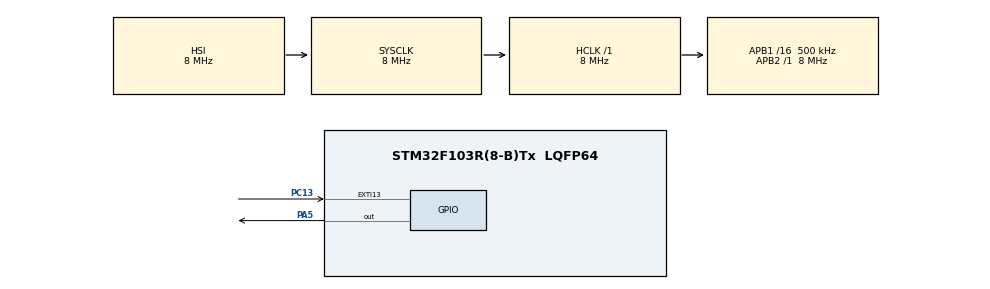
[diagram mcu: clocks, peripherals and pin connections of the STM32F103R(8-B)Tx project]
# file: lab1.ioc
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Mcu.Family=STM32F1
Mcu.Name=STM32F103R(8-B)Tx
Mcu.Package=LQFP64
NVIC.PriorityGroup=NVIC_PRIORITYGROUP_4
PA13.GPIO_Label=TMS
PA13.Mode=Serial_Wire
PA13.Signal=SYS_JTMS-SWDIO
PA14.GPIO_Label=TCK
PA14.Mode=Serial_Wire
PA14.Signal=SYS_JTCK-SWCLK
PA2.GPIO_Label=USART_TX
PA2.GPIO_Mode=GPIO_MODE_AF_PP
PA2.GPIO_PuPd=GPIO_NOPULL
PA2.GPIO_Speed=GPIO_SPEED_FREQ_LOW
PA2.Signal=USART2_TX
PA3.GPIO_Label=USART_RX
PA3.GPIO_Mode=GPIO_MODE_AF_PP
PA3.GPIO_PuPd=GPIO_NOPULL
PA3.GPIO_Speed=GPIO_SPEED_FREQ_LOW
PA3.Signal=USART2_RX
PA5.Signal=GPIO_Output
PB3.GPIO_Label=SWO
PB3.Signal=SYS_JTDO-TRACESWO
PB6.Signal=S_TIM4_CH1
PC13-TAMPER-RTC.Signal=GPXTI13
PC14-OSC32_IN.Signal=RCC_OSC32_IN
PC15-OSC32_OUT.Signal=RCC_OSC32_OUT
PD0-OSC_IN.Signal=RCC_OSC_IN
PD1-OSC_OUT.Signal=RCC_OSC_OUT
ProjectManager.HeapSize=0x200
ProjectManager.StackSize=0x400
ProjectManager.TargetToolchain=STM32CubeIDE
RCC.AHBFreq_Value=8000000
RCC.APB1CLKDivider=RCC_HCLK_DIV16
RCC.APB1Freq_Value=500000
RCC.APB1TimFreq_Value=1000000
RCC.APB2Freq_Value=8000000
RCC.APB2TimFreq_Value=8000000
RCC.HCLKFreq_Value=8000000
RCC.PLLMUL=RCC_PLL_MUL16
RCC.SYSCLKFreq_VALUE=8000000
RCC.USBFreq_Value=64000000
SH.S_TIM4_CH1.0=TIM4_CH1
TIM4.Period=65535
TIM4.Prescaler=10
VP_TIM4_VS_ClockSourceINT.Mode=Internal
board=NUCLEO-F103RB

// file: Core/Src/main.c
/* USER CODE BEGIN Header */
/**
  ******************************************************************************
  * @file           : main.c
  * @brief          : Main program body
  ******************************************************************************
  * @attention
  *
  * <h2><center>&copy; Copyright (c) 2020 STMicroelectronics.
  * All rights reserved.</center></h2>
  *
  * This software component is licensed by ST under BSD 3-Clause license,
  * the "License"; You may not use this file except in compliance with the
  * License. You may obtain a copy of the License at:
  *                        opensource.org/licenses/BSD-3-Clause
  *
  ******************************************************************************
  */
/* USER CODE END Header */

#include "main.h"

TIM_HandleTypeDef htim4;

void SystemClock_Config(void);
static void MX_GPIO_Init(void);
static void MX_TIM4_Init(void);

int main(void)
{

  /* MCU Configuration--------------------------------------------------------*/

  /* Reset of all peripherals, Initializes the Flash interface and the Systick. */
  HAL_Init();

  /* Configure the system clock */
  SystemClock_Config();

  /* Initialize all configured peripherals */
  MX_GPIO_Init();
  MX_TIM4_Init();

  /* Infinite loop */
  while (1)
  {

    /* USER CODE BEGIN 3 */
	  if(__HAL_TIM_GET_COUNTER(&htim4) == 0x00)
	  {
		  HAL_GPIO_TogglePin(GPIOA,GPIO_PIN_5);
	  }
	  //HAL_Delay(1000);
  }
  /* USER CODE END 3 */
}

void SystemClock_Config(void)
{
  RCC_OscInitTypeDef RCC_OscInitStruct = {0};
  RCC_ClkInitTypeDef RCC_ClkInitStruct = {0};

  /** Initializes the CPU, AHB and APB busses clocks
  */
  RCC_OscInitStruct.OscillatorType = RCC_OSCILLATORTYPE_HSI;
  RCC_OscInitStruct.HSIState = RCC_HSI_ON;
  RCC_OscInitStruct.HSICalibrationValue = RCC_HSICALIBRATION_DEFAULT;
  RCC_OscInitStruct.PLL.PLLState = RCC_PLL_NONE;
  if (HAL_RCC_OscConfig(&RCC_OscInitStruct) != HAL_OK)
  {
    Error_Handler();
  }
  /** Initializes the CPU, AHB and APB busses clocks
  */
  RCC_ClkInitStruct.ClockType = RCC_CLOCKTYPE_HCLK|RCC_CLOCKTYPE_SYSCLK
                              |RCC_CLOCKTYPE_PCLK1|RCC_CLOCKTYPE_PCLK2;
  RCC_ClkInitStruct.SYSCLKSource = RCC_SYSCLKSOURCE_HSI;
  RCC_ClkInitStruct.AHBCLKDivider = RCC_SYSCLK_DIV1;
  RCC_ClkInitStruct.APB1CLKDivider = RCC_HCLK_DIV16;
  RCC_ClkInitStruct.APB2CLKDivider = RCC_HCLK_DIV1;

  if (HAL_RCC_ClockConfig(&RCC_ClkInitStruct, FLASH_LATENCY_0) != HAL_OK)
  {
    Error_Handler();
  }
}

static void MX_TIM4_Init(void)
{

  TIM_ClockConfigTypeDef sClockSourceConfig = {0};
  TIM_MasterConfigTypeDef sMasterConfig = {0};

  /* USER CODE BEGIN TIM4_Init 1 */
  __HAL_RCC_TIM4_CLK_ENABLE();

  /* USER CODE END TIM4_Init 1 */
  htim4.Instance = TIM4;
  htim4.Init.Prescaler = 10;
  htim4.Init.CounterMode = TIM_COUNTERMODE_UP;
  htim4.Init.Period = 65535;
  htim4.Init.ClockDivision = TIM_CLOCKDIVISION_DIV1;
  htim4.Init.AutoReloadPreload = TIM_AUTORELOAD_PRELOAD_DISABLE;
  if (HAL_TIM_Base_Init(&htim4) != HAL_OK)
  {
    Error_Handler();
  }
  sClockSourceConfig.ClockSource = TIM_CLOCKSOURCE_INTERNAL;
  if (HAL_TIM_ConfigClockSource(&htim4, &sClockSourceConfig) != HAL_OK)
  {
    Error_Handler();
  }
  sMasterConfig.MasterOutputTrigger = TIM_TRGO_RESET;
  sMasterConfig.MasterSlaveMode = TIM_MASTERSLAVEMODE_DISABLE;
  if (HAL_TIMEx_MasterConfigSynchronization(&htim4, &sMasterConfig) != HAL_OK)
  {
    Error_Handler();
  }
  /* USER CODE BEGIN TIM4_Init 2 */
  HAL_TIM_Base_MspInit(&htim4);
  HAL_TIM_Base_Init(&htim4);
  HAL_TIM_Base_Start(&htim4);

  /* USER CODE END TIM4_Init 2 */

}

static void MX_GPIO_Init(void)
{
  GPIO_InitTypeDef GPIO_InitStruct = {0};

  /* GPIO Ports Clock Enable */
  __HAL_RCC_GPIOC_CLK_ENABLE();
  __HAL_RCC_GPIOD_CLK_ENABLE();
  __HAL_RCC_GPIOA_CLK_ENABLE();
  __HAL_RCC_GPIOB_CLK_ENABLE();

  /*Configure GPIO pin Output Level */
  HAL_GPIO_WritePin(GPIOA, GPIO_PIN_5, GPIO_PIN_RESET);

  /*Configure GPIO pin : PC13 */
  GPIO_InitStruct.Pin = GPIO_PIN_13;
  GPIO_InitStruct.Mode = GPIO_MODE_IT_RISING;
  GPIO_InitStruct.Pull = GPIO_NOPULL;
  HAL_GPIO_Init(GPIOC, &GPIO_InitStruct);

  /*Configure GPIO pins : USART_TX_Pin USART_RX_Pin */
  GPIO_InitStruct.Pin = USART_TX_Pin|USART_RX_Pin;
  GPIO_InitStruct.Mode = GPIO_MODE_AF_PP;
  GPIO_InitStruct.Speed = GPIO_SPEED_FREQ_LOW;
  HAL_GPIO_Init(GPIOA, &GPIO_InitStruct);

  /*Configure GPIO pin : PA5 */
  GPIO_InitStruct.Pin = GPIO_PIN_5;
  GPIO_InitStruct.Mode = GPIO_MODE_OUTPUT_PP;
  GPIO_InitStruct.Pull = GPIO_NOPULL;
  GPIO_InitStruct.Speed = GPIO_SPEED_FREQ_LOW;
  HAL_GPIO_Init(GPIOA, &GPIO_InitStruct);

}

void Error_Handler(void)
{
}

/************************ (C) COPYRIGHT STMicroelectronics *****END OF FILE****/
